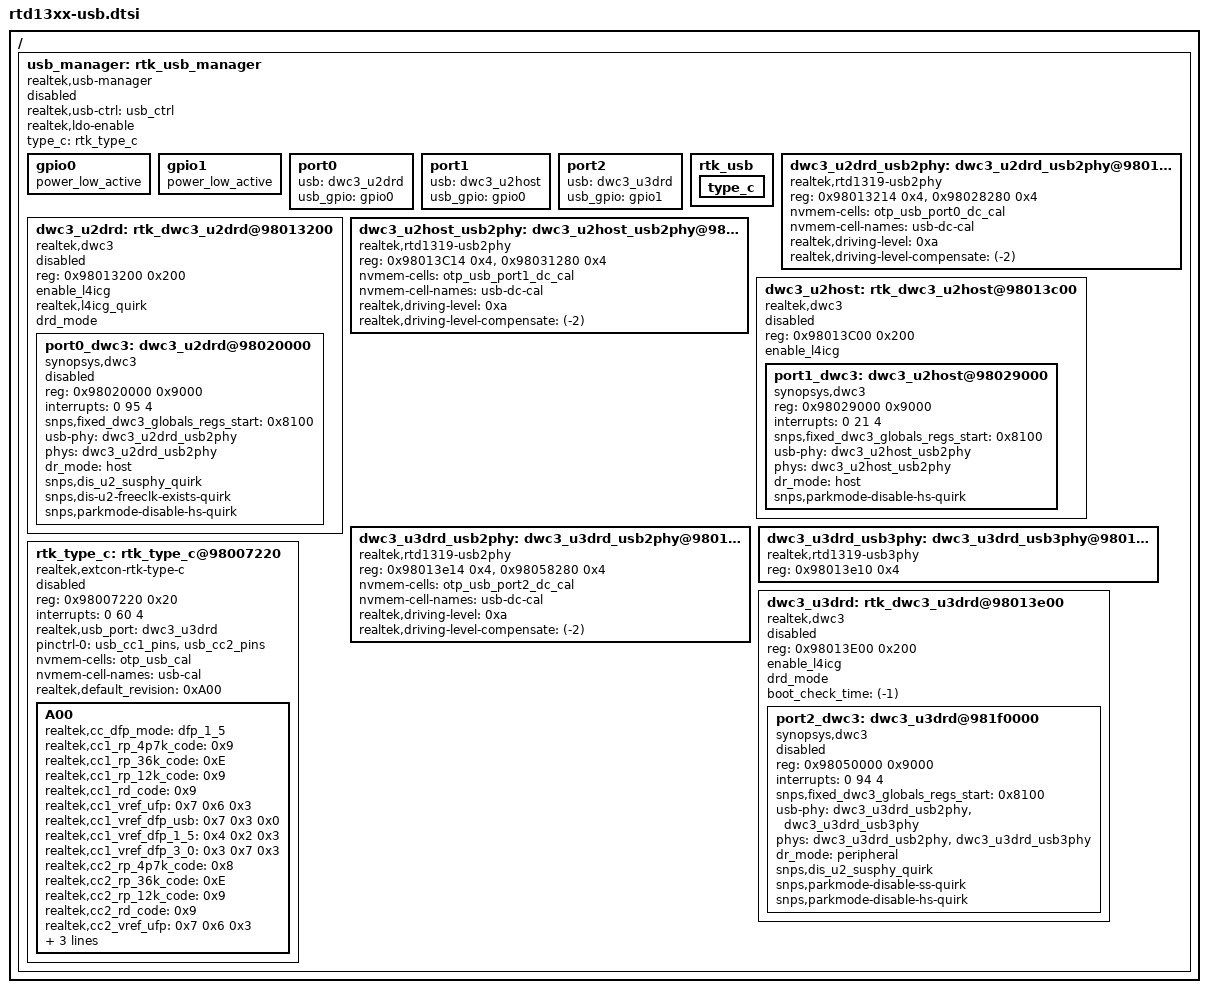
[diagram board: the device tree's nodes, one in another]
// SPDX-License-Identifier: (GPL-2.0-or-later OR BSD-2-Clause)
/*
 * Realtek RTD13xx SoC USB
 *
 * Copyright (c) 2020 Realtek Semiconductor Corp.
 */

/ {
	usb_manager: rtk_usb_manager {
		compatible = "realtek,usb-manager";
		#address-cells = <1>;
		#size-cells = <1>;
		ranges;

		//usb_iso_mode;  /* ISO mode is only port suspend (Default disable) */
		//en_usb_storage_reprobe; /* To enable usb storage re-probe*/
		//rescue_usb; /* For rescue dtb use */
		realtek,usb-ctrl = <&usb_ctrl>;
		realtek,ldo-enable;

		status = "disabled";

		/* set type c node */
		type_c = <&rtk_type_c>;

		gpio0: gpio0 {
			//realtek,power-gpio = <&gpio 48 GPIO_ACTIVE_HIGH>;
			power_low_active;
		};

		gpio1: gpio1 {
			//realtek,power-gpio = <&gpio 49 GPIO_ACTIVE_HIGH>;
			power_low_active;
		};

		port0 {
			usb = <&dwc3_u2drd>;
			usb_gpio = <&gpio0>;
		};

		port1 {
			usb = <&dwc3_u2host>;
			usb_gpio = <&gpio0>;
		};

		port2 {
			usb = <&dwc3_u3drd>;
			usb_gpio = <&gpio1>;
		};

		rtk_usb {
			//pcie_usb3phy_sel = <0x9800705c>; /* Only for RTD1319 */

			type_c {
				/* For 1315, 1317, u2drd */
				//realtek,connector_switch-gpio = <&gpio 25 GPIO_ACTIVE_HIGH>;
				/* For 1319, u3drd */
				//realtek,plug_side_switch-gpio = <&gpio 53 GPIO_ACTIVE_HIGH>;
			};
		};
	};
};

&usb_manager {
	dwc3_u2drd_usb2phy: dwc3_u2drd_usb2phy@98013214 {
		compatible = "realtek,rtd1319-usb2phy";
		reg = <0x98013214 0x4>, <0x98028280 0x4>;
		#phy-cells = <0>;
		nvmem-cells = <&otp_usb_port0_dc_cal>;
		nvmem-cell-names = "usb-dc-cal";
		status = "okay";

		realtek,driving-level = <0xa>;
		realtek,driving-level-compensate = <(-2)>;
	};

	dwc3_u2drd: rtk_dwc3_u2drd@98013200 {
		compatible = "realtek,dwc3", "syscon";
		reg = <0x98013200 0x200>;
		#address-cells = <1>;
		#size-cells = <1>;
		ranges;
		enable_l4icg;
		realtek,l4icg_quirk;
		drd_mode;
		status = "disabled";

		port0_dwc3: dwc3_u2drd@98020000 {
			compatible = "synopsys,dwc3", "syscon";
			reg = <0x98020000 0x9000>;
			interrupts = <0 95 4>;
			snps,fixed_dwc3_globals_regs_start = <0x8100>;
			usb-phy = <&dwc3_u2drd_usb2phy>;
			phys = <&dwc3_u2drd_usb2phy>;
			phy-names = "usb2-phy";
			dr_mode = "host"; /*host, peripheral*/
			snps,dis_u2_susphy_quirk; // Disable u2phy suspend for drd
			snps,dis-u2-freeclk-exists-quirk; // Fixed u2drd host die issue
			snps,parkmode-disable-hs-quirk; // disable usb2.0 park mode

			status = "disabled";
		};
	};

	dwc3_u2host_usb2phy: dwc3_u2host_usb2phy@98013c14 {
		compatible = "realtek,rtd1319-usb2phy";
		reg = <0x98013C14 0x4>, <0x98031280 0x4>;
		#phy-cells = <0>;
		nvmem-cells = <&otp_usb_port1_dc_cal>;
		nvmem-cell-names = "usb-dc-cal";
		status = "okay";

		realtek,driving-level = <0xa>;
		realtek,driving-level-compensate = <(-2)>;
	};

	dwc3_u2host: rtk_dwc3_u2host@98013c00 {
		compatible = "realtek,dwc3", "syscon";
		reg = <0x98013C00 0x200>;
		#address-cells = <1>;
		#size-cells = <1>;
		ranges;
		enable_l4icg;
		status = "disabled";

		port1_dwc3: dwc3_u2host@98029000 {
			compatible = "synopsys,dwc3", "syscon";
			reg = <0x98029000 0x9000>;
			interrupts = <0 21 4>;
			snps,fixed_dwc3_globals_regs_start = <0x8100>;
			usb-phy = <&dwc3_u2host_usb2phy>;
			phys = <&dwc3_u2host_usb2phy>;
			phy-names = "usb2-phy";
			dr_mode = "host"; /*only host*/
			snps,parkmode-disable-hs-quirk; // disable usb2.0 park mode
		};
	};

	dwc3_u3drd_usb2phy: dwc3_u3drd_usb2phy@98013e14 {
		compatible = "realtek,rtd1319-usb2phy";
		reg = <0x98013e14 0x4>, <0x98058280 0x4>;
		#phy-cells = <0>;
		nvmem-cells = <&otp_usb_port2_dc_cal>;
		nvmem-cell-names = "usb-dc-cal";
		status = "okay";

		realtek,driving-level = <0xa>;
		realtek,driving-level-compensate = <(-2)>;
	};

	dwc3_u3drd_usb3phy: dwc3_u3drd_usb3phy@98013e10 {
		compatible = "realtek,rtd1319-usb3phy";
		reg = <0x98013e10 0x4>;
		#phy-cells = <0>;
		status = "okay";
	};

	dwc3_u3drd: rtk_dwc3_u3drd@98013e00 {
		compatible = "realtek,dwc3", "syscon";
		reg = <0x98013E00 0x200>;
		#address-cells = <1>;
		#size-cells = <1>;
		ranges;
		enable_l4icg;
		drd_mode;
		boot_check_time = <(-1)>; /* ms (At boot Device switch Host time) */
		status = "disabled";

		port2_dwc3: dwc3_u3drd@981f0000 {
			compatible = "synopsys,dwc3", "syscon";
			reg = <0x98050000 0x9000>;
			interrupts = <0 94 4>;
			snps,fixed_dwc3_globals_regs_start = <0x8100>;
			usb-phy = <&dwc3_u3drd_usb2phy &dwc3_u3drd_usb3phy>;
			phys = <&dwc3_u3drd_usb2phy &dwc3_u3drd_usb3phy>;
			phy-names = "usb2-phy", "usb3-phy";
			dr_mode = "peripheral"; /*host, peripheral*/
			snps,dis_u2_susphy_quirk; // Disable u2phy suspend for drd
			snps,parkmode-disable-ss-quirk; // disable usb3.0 park mode
			snps,parkmode-disable-hs-quirk; // disable usb2.0 park mode

			status = "disabled";
		};
	};

	rtk_type_c: rtk_type_c@98007220 {
		compatible= "realtek,extcon-rtk-type-c";
		reg = <0x98007220 0x20>;
		interrupts = <0 60 4>;
		//debug; /*to enable debug log*/

		realtek,usb_port = <&dwc3_u3drd>;

		pinctrl-names = "default";
		pinctrl-0 = <&usb_cc1_pins>, <&usb_cc2_pins>;

		nvmem-cells = <&otp_usb_cal>;
		nvmem-cell-names = "usb-cal";

		status = "disabled";

		realtek,default_revision = <0xA00>;
		A00 {
			realtek,cc_dfp_mode = "dfp_1_5"; /*dfp_3_0, dfp_1_5, dfp_usb*/
			realtek,cc1_rp_4p7k_code = <0x9>;
			realtek,cc1_rp_36k_code = <0xE>;
			realtek,cc1_rp_12k_code = <0x9>;
			realtek,cc1_rd_code = <0x9>;
			realtek,cc1_vref_ufp = /bits/ 8
				<0x7 0x6 0x3>; /*<1p23v,0p66v,0p2v>*/
			realtek,cc1_vref_dfp_usb = /bits/ 8
				<0x7 0x3 0x0>; /*<0_1p6v,0p2v,unused>*/
			realtek,cc1_vref_dfp_1_5 = /bits/ 8
				<0x4 0x2 0x3>; /*<1_1p6v,0p4v,0p2v>*/
			realtek,cc1_vref_dfp_3_0 = /bits/ 8
				<0x3 0x7 0x3>; /*<2p6v,0p8v,0p2v>*/
			realtek,cc2_rp_4p7k_code = <0x8>;
			realtek,cc2_rp_36k_code = <0xE>;
			realtek,cc2_rp_12k_code = <0x9>;
			realtek,cc2_rd_code = <0x9>;
			realtek,cc2_vref_ufp = /bits/ 8
				<0x7 0x6 0x3>; /*<1p23v,0p66v,0p2v>*/
			realtek,cc2_vref_dfp_usb = /bits/ 8
				<0x7 0x3 0x0>; /*<0_1p6v,0p2v,unused>*/
			realtek,cc2_vref_dfp_1_5 = /bits/ 8
				<0x6 0x3 0x3>; /*<1_1p6v,0p4v,0p2v>*/
			realtek,cc2_vref_dfp_3_0 = /bits/ 8
				<0x3 0x7 0x3>; /*<2p6v,0p8v,0p2v>*/
		};
	};

};
